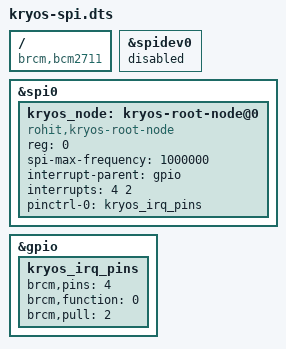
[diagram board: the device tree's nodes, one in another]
/dts-v1/;
/plugin/;
/ {
    compatible = "brcm,bcm2711";

    fragment@0 {
        target = <&spidev0>;
        __overlay__ {
            status = "disabled";
        };
    };

    fragment@1 {
        target = <&spi0>;
        __overlay__ {
            #address-cells = <1>;
            #size-cells = <0>;
            status = "okay";

            kryos_node: kryos-root-node@0 {
                compatible = "rohit,kryos-root-node";
                reg = <0>;
                spi-max-frequency = <1000000>;
                status = "okay";
                interrupt-parent = <&gpio>;
                interrupts = <4 2>; /* GPIO 4, Falling Edge (2) */
                interrupt-names = "kryos-irq";
                pinctrl-names = "default";
                pinctrl-0 = <&kryos_irq_pins>;
            };
        };
    };

    fragment@2 {
        target = <&gpio>;
        __overlay__ {
            kryos_irq_pins: kryos_irq_pins {
                brcm,pins = <4>;       /* GPIO 4 (Physical Pin 7) */
                brcm,function = <0>;    /* input */
                brcm,pull = <2>;        /* pull-up */
            };
        };
    };
};
